# EFM32JG12B500F1024IL125 register map
File version: 4.0.0
CPU: CM3 r2p1, little endian, MPU, no FPU, 3 interrupt priority bits
Registers are 32-bit, read-write, reset 0x0 unless marked. A register's access mark holds for its fields unless they carry their own. Offsets are from the block's base; [hi:lo] are bit positions; {n}, {i} and the like mark numbered series.

## PCNT0
Base 0x4004E000
Same registers: PCNT1 0x4004E400, PCNT2 0x4004E800
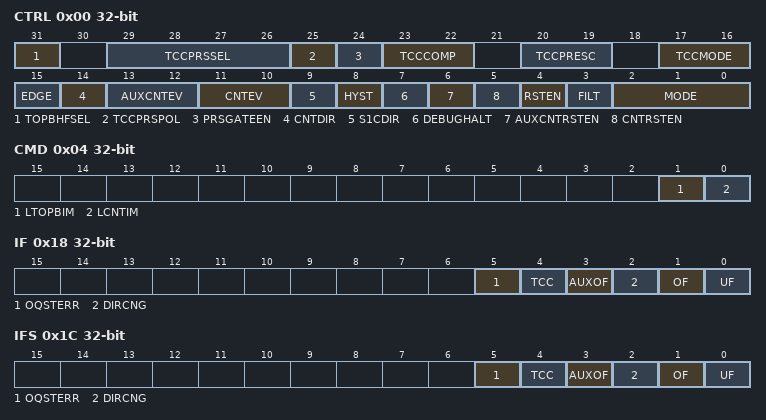
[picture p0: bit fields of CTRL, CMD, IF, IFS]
0x00 CTRL — Control Register
  [31] TOPBHFSEL — TOPB High Frequency Value Select
  [29:26] TCCPRSSEL — TCC PRS Channel Select
    {v}=PRSCH{v} (PRS Channel {v} selected.) (v=0..11)
  [25] TCCPRSPOL — TCC PRS Polarity Select
  [24] PRSGATEEN — PRS Gate Enable
  [23:22] TCCCOMP — Triggered Compare and Clear Compare Mode
    0=LTOE (Compare match if PCNT_CNT is less than, or equal to PCNT_TOP.); 1=GTOE (Compare match if PCNT_CNT is greater than or equal to PCNT_TOP.); 2=RANGE (Compare match if PCNT_CNT is less than, or equal to PCNT_TOP[15:8]], and greater than, or equal to PCNT_TOP[7:0].)
  [20:19] TCCPRESC — Set the LFA Prescaler for Triggered Compare and Clear
    0=DIV1 (Compare and clear event each LFA cycle.); 1=DIV2 (Compare and clear performed on every other LFA cycle.); 2=DIV4 (Compare and clear performed on every 4th LFA cycle.); 3=DIV8 (Compare and clear performed on every 8th LFA cycle.)
  [17:16] TCCMODE — Sets the Mode for Triggered Compare and Clear
    0=DISABLED (Triggered compare and clear not enabled.); 1=LFA (Compare and clear performed on each (optionally prescaled) LFA clock cycle.); 2=PRS (Compare and clear performed on positive PRS edges.)
  [15] EDGE — Edge Select
  [14] CNTDIR — Non-Quadrature Mode Counter Direction Control
  [13:12] AUXCNTEV — Controls When the Auxiliary Counter Counts
    0=NONE (Never counts.); 1=UP (Counts up on up-count events.); 2=DOWN (Counts up on down-count events.); 3=BOTH (Counts up on both up-count and down-count events.)
  [11:10] CNTEV — Controls When the Counter Counts
    0=BOTH (Counts up on up-count and down on down-count events.); 1=UP (Only counts up on up-count events.); 2=DOWN (Only counts down on down-count events.); 3=NONE (Never counts.)
  [9] S1CDIR — Count Direction Determined By S1
  [8] HYST — Enable Hysteresis
  [7] DEBUGHALT — Debug Mode Halt Enable
  [6] AUXCNTRSTEN — Enable AUXCNT Reset
  [5] CNTRSTEN — Enable CNT Reset
  [4] RSTEN — Enable PCNT Clock Domain Reset
  [3] FILT — Enable Digital Pulse Width Filter
  [2:0] MODE — Mode Select
    0=DISABLE (The module is disabled.); 1=OVSSINGLE (Single input LFACLK oversampling mode (available in EM0-EM3).); 2=EXTCLKSINGLE (Externally clocked single input counter mode (available in EM0-EM3).); 3=EXTCLKQUAD (Externally clocked quadrature decoder mode (available in EM0-EM3).); 4=OVSQUAD1X (LFACLK oversampling quadrature decoder 1X mode (available in EM0-EM3).); 5=OVSQUAD2X (LFACLK oversampling quadrature decoder 2X mode (available in EM0-EM3).); 6=OVSQUAD4X (LFACLK oversampling quadrature decoder 4X mode (available in EM0-EM3).)
0x04 CMD wo — Command Register
  [1] LTOPBIM — Load TOPB Immediately
  [0] LCNTIM — Load CNT Immediately
0x08 STATUS ro
  [0] DIR — Current Counter Direction
0x0C CNT ro — Counter Value Register
  [15:0] CNT — Counter Value
0x10 TOP ro reset 0xFF — Top Value Register
  [15:0] TOP — Counter Top Value
0x14 TOPB reset 0xFF — Top Value Buffer Register
  [15:0] TOPB — Counter Top Buffer
0x18 IF ro — Interrupt Flag Register
  [5] OQSTERR — Oversampling Quadrature State Error Interrupt
  [4] TCC — Triggered Compare Interrupt Read Flag
  [3] AUXOF — Auxiliary Overflow Interrupt Read Flag
  [2] DIRCNG — Direction Change Detect Interrupt Flag
  [1] OF — Overflow Interrupt Read Flag
  [0] UF — Underflow Interrupt Read Flag
0x1C IFS wo — Interrupt Flag Set Register
  [5] OQSTERR — Set OQSTERR Interrupt Flag
  [4] TCC — Set TCC Interrupt Flag
  [3] AUXOF — Set AUXOF Interrupt Flag
  [2] DIRCNG — Set DIRCNG Interrupt Flag
  [1] OF — Set OF Interrupt Flag
  [0] UF — Set UF Interrupt Flag
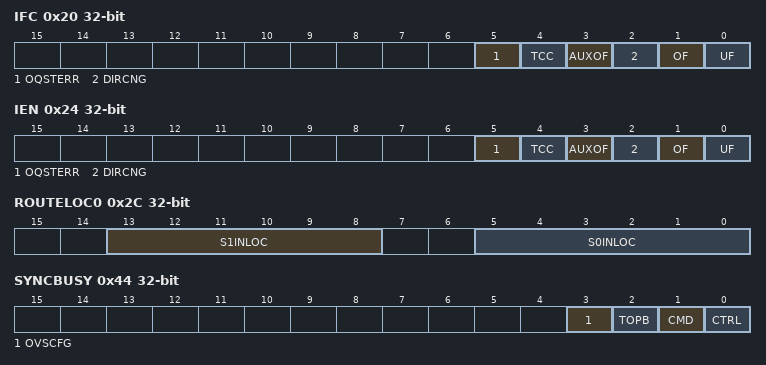
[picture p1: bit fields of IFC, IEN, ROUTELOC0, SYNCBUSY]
0x20 IFC wo — Interrupt Flag Clear Register
  [5] OQSTERR — Clear OQSTERR Interrupt Flag
  [4] TCC — Clear TCC Interrupt Flag
  [3] AUXOF — Clear AUXOF Interrupt Flag
  [2] DIRCNG — Clear DIRCNG Interrupt Flag
  [1] OF — Clear OF Interrupt Flag
  [0] UF — Clear UF Interrupt Flag
0x24 IEN — Interrupt Enable Register
  [5] OQSTERR — OQSTERR Interrupt Enable
  [4] TCC — TCC Interrupt Enable
  [3] AUXOF — AUXOF Interrupt Enable
  [2] DIRCNG — DIRCNG Interrupt Enable
  [1] OF — OF Interrupt Enable
  [0] UF — UF Interrupt Enable
0x2C ROUTELOC0 — I/O Routing Location Register
  [13:8] S1INLOC — I/O Location
    {v}=LOC{v} (Location {v}) (v=0..31)
  [5:0] S0INLOC — I/O Location
    {v}=LOC{v} (Location {v}) (v=0..31)
0x40 FREEZE
  [0] REGFREEZE — Register Update Freeze
0x44 SYNCBUSY ro — Synchronization Busy Register
  [3] OVSCFG — OVSCFG Register Busy
  [2] TOPB — TOPB Register Busy
  [1] CMD — CMD Register Busy
  [0] CTRL — CTRL Register Busy
0x64 AUXCNT ro — Auxiliary Counter Value Register
  [15:0] AUXCNT — Auxiliary Counter Value
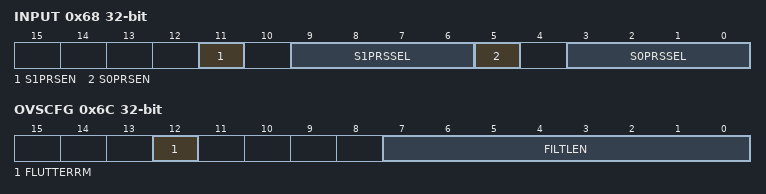
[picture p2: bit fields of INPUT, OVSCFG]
0x68 INPUT — PCNT Input Register
  [11] S1PRSEN — S1IN PRS Enable
  [9:6] S1PRSSEL — S1IN PRS Channel Select
    {v}=PRSCH{v} (PRS Channel {v} selected.) (v=0..11)
  [5] S0PRSEN — S0IN PRS Enable
  [3:0] S0PRSSEL — S0IN PRS Channel Select
    {v}=PRSCH{v} (PRS Channel {v} selected.) (v=0..11)
0x6C OVSCFG — Oversampling Config Register
  [12] FLUTTERRM — Flutter Remove
  [7:0] FILTLEN — Configure Filter Length for Inputs S0IN and S1IN

## Notices in the file
# License
Copyright 2021 Silicon Laboratories Inc. www.silabs.com
SPDX-License-Identifier: Zlib
The licensor of this software is Silicon Laboratories Inc.
This software is provided 'as-is', without any express or implied
warranty. In no event will the authors be held liable for any damages
arising from the use of this software.
Permission is granted to anyone to use this software for any purpose,
including commercial applications, and to alter it and redistribute it
freely, subject to the following restrictions:
1. The origin of this software must not be misrepresented; you must not
claim that you wrote the original software. If you use this software
in a product, an acknowledgment in the product documentation would be
appreciated but is not required.
2. Altered source versions must be plainly marked as such, and must not be
misrepresented as being the original software.
3. This notice may not be removed or altered from any source distribution.
